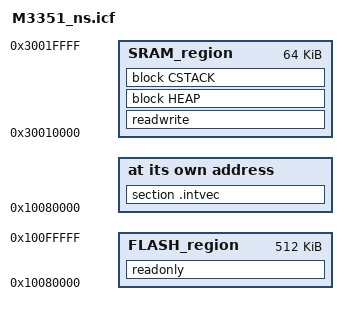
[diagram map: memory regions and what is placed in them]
/*###ICF### Section handled by ICF editor, don't touch! ****/
/*-Editor annotation file-*/
/* IcfEditorFile="$TOOLKIT_DIR$\config\ide\IcfEditor\cortex_v1_0.xml" */
/*-Specials-*/
define symbol __ICFEDIT_intvec_start__ = 0x10080000;
/*-Memory Regions-*/
define symbol __ICFEDIT_region_FLASH_start__  = 0x10080000;
define symbol __ICFEDIT_region_FLASH_end__    = 0x100FFFFF;
define symbol __ICFEDIT_region_SRAM_start__ = 0x30010000;
define symbol __ICFEDIT_region_SRAM_end__   = 0x3001FFFF;

/*-Sizes-*/
define symbol __ICFEDIT_size_cstack__ = 0x00001000;
define symbol __ICFEDIT_size_heap__   = 0x00008000;
/**** End of ICF editor section. ###ICF###*/


define memory mem with size = 4G;
define region FLASH_region   = mem:[from __ICFEDIT_region_FLASH_start__   to __ICFEDIT_region_FLASH_end__];
define region SRAM_region   = mem:[from __ICFEDIT_region_SRAM_start__   to __ICFEDIT_region_SRAM_end__];

define block CSTACK    with alignment = 8, size = __ICFEDIT_size_cstack__   { };
define block HEAP      with alignment = 8, size = __ICFEDIT_size_heap__     { };

initialize by copy { readwrite };

do not initialize  { section .noinit };

place at address mem:__ICFEDIT_intvec_start__ { section .intvec };

place in FLASH_region   { readonly};
place in SRAM_region   { readwrite, block HEAP, block CSTACK };

